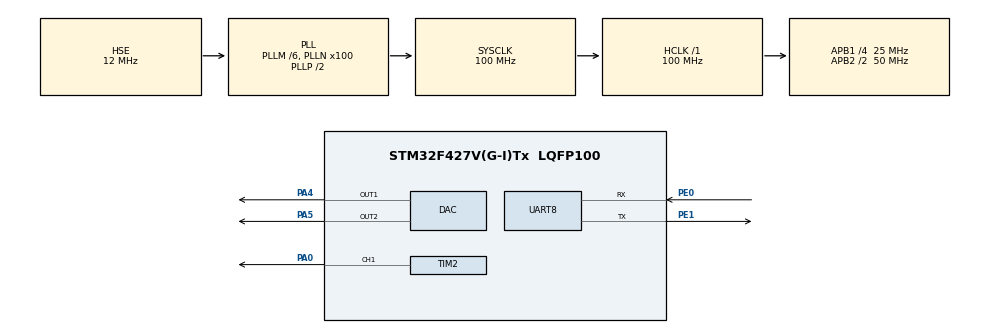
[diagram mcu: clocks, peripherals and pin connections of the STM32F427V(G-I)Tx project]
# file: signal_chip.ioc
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DAC.DAC_Trigger=DAC_TRIGGER_SOFTWARE
DAC.DAC_Trigger2=DAC_TRIGGER_SOFTWARE
Mcu.Family=STM32F4
Mcu.Name=STM32F427V(G-I)Tx
Mcu.Package=LQFP100
NVIC.PriorityGroup=NVIC_PRIORITYGROUP_2
NVIC.UART8_IRQn=true\:2\:2\:true\:false\:true\:true\:true
PA0/WKUP.Signal=S_TIM2_CH1_ETR
PA13.Mode=Serial_Wire
PA13.Signal=SYS_JTMS-SWDIO
PA14.Mode=Serial_Wire
PA14.Signal=SYS_JTCK-SWCLK
PA4.Signal=COMP_DAC1_group
PA5.Signal=COMP_DAC2_group
PE0.Mode=Asynchronous
PE0.Signal=UART8_RX
PE1.Mode=Asynchronous
PE1.Signal=UART8_TX
PH0/OSC_IN.Mode=HSE-External-Oscillator
PH0/OSC_IN.Signal=RCC_OSC_IN
PH1/OSC_OUT.Mode=HSE-External-Oscillator
PH1/OSC_OUT.Signal=RCC_OSC_OUT
ProjectManager.HeapSize=0x200
ProjectManager.StackSize=0x400
ProjectManager.TargetToolchain=MDK-ARM V5
RCC.48MHZClocksFreq_Value=50000000
RCC.AHBFreq_Value=100000000
RCC.APB1CLKDivider=RCC_HCLK_DIV4
RCC.APB1Freq_Value=25000000
RCC.APB1TimFreq_Value=50000000
RCC.APB2CLKDivider=RCC_HCLK_DIV2
RCC.APB2Freq_Value=50000000
RCC.APB2TimFreq_Value=100000000
RCC.CortexFreq_Value=100000000
RCC.HCLKFreq_Value=100000000
RCC.HSE_VALUE=12000000
RCC.HSI_VALUE=16000000
RCC.LSE_VALUE=32768
RCC.PLLM=6
RCC.PLLN=100
RCC.PLLSourceVirtual=RCC_PLLSOURCE_HSE
RCC.SYSCLKFreq_VALUE=100000000
RCC.SYSCLKSource=RCC_SYSCLKSOURCE_PLLCLK
RCC.VCOOutputFreq_Value=200000000
SH.COMP_DAC1_group.0=DAC_OUT1,DAC_OUT1
SH.COMP_DAC2_group.0=DAC_OUT2,DAC_OUT2
SH.S_TIM2_CH1_ETR.0=TIM2_CH1,Output Compare1 CH1
TIM2.Channel-Output\ Compare1\ CH1=TIM_CHANNEL_1
TIM2.Period=1000
TIM2.Prescaler=50
UART8.VirtualMode=Asynchronous
VP_TIM2_VS_ClockSourceINT.Mode=Internal
board=custom

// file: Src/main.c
/* USER CODE BEGIN Header */
/**
  ******************************************************************************
  * @file           : main.c
  * @brief          : Main program body
  ******************************************************************************
  * @attention
  *
  * <h2><center>&copy; Copyright (c) 2019 STMicroelectronics.
  * All rights reserved.</center></h2>
  *
  * This software component is licensed by ST under BSD 3-Clause license,
  * the "License"; You may not use this file except in compliance with the
  * License. You may obtain a copy of the License at:
  *                        opensource.org/licenses/BSD-3-Clause
  *
  ******************************************************************************
  */
/* USER CODE END Header */

#include "main.h"

/* USER CODE BEGIN Includes */
#include "set_coordinates.h"

/* USER CODE END Includes */

DAC_HandleTypeDef hdac;

TIM_HandleTypeDef htim2;

UART_HandleTypeDef huart8;

void SystemClock_Config(void);
static void MX_GPIO_Init(void);
static void MX_DAC_Init(void);
static void MX_TIM2_Init(void);
static void MX_UART8_Init(void);

/* USER CODE BEGIN 0 */
void HAL_UART_RxCpltCallback(UART_HandleTypeDef *huart)
{
  /* Prevent unused argument(s) compilation warning */
  //UNUSED(huart);
  /* NOTE: This function should not be modified, when the callback is needed,
           the HAL_UART_RxCpltCallback could be implemented in the user file
   */
}
/* USER CODE END 0 */

int main(void)
{

  /* MCU Configuration--------------------------------------------------------*/

  /* Reset of all peripherals, Initializes the Flash interface and the Systick. */
  HAL_Init();

  /* Configure the system clock */
  SystemClock_Config();

  /* Initialize all configured peripherals */
  MX_GPIO_Init();
  MX_DAC_Init();
  MX_TIM2_Init();
  MX_UART8_Init();

  /* Infinite loop */
  while (1)
  {

    /* USER CODE BEGIN 3 */
		set_coordinate();
  }
  /* USER CODE END 3 */
}

void SystemClock_Config(void)
{
  RCC_OscInitTypeDef RCC_OscInitStruct = {0};
  RCC_ClkInitTypeDef RCC_ClkInitStruct = {0};

  /** Configure the main internal regulator output voltage
  */
  __HAL_RCC_PWR_CLK_ENABLE();
  __HAL_PWR_VOLTAGESCALING_CONFIG(PWR_REGULATOR_VOLTAGE_SCALE3);
  /** Initializes the CPU, AHB and APB busses clocks
  */
  RCC_OscInitStruct.OscillatorType = RCC_OSCILLATORTYPE_HSE;
  RCC_OscInitStruct.HSEState = RCC_HSE_ON;
  RCC_OscInitStruct.PLL.PLLState = RCC_PLL_ON;
  RCC_OscInitStruct.PLL.PLLSource = RCC_PLLSOURCE_HSE;
  RCC_OscInitStruct.PLL.PLLM = 6;
  RCC_OscInitStruct.PLL.PLLN = 100;
  RCC_OscInitStruct.PLL.PLLP = RCC_PLLP_DIV2;
  RCC_OscInitStruct.PLL.PLLQ = 4;
  if (HAL_RCC_OscConfig(&RCC_OscInitStruct) != HAL_OK)
  {
    Error_Handler();
  }
  /** Initializes the CPU, AHB and APB busses clocks
  */
  RCC_ClkInitStruct.ClockType = RCC_CLOCKTYPE_HCLK|RCC_CLOCKTYPE_SYSCLK
                              |RCC_CLOCKTYPE_PCLK1|RCC_CLOCKTYPE_PCLK2;
  RCC_ClkInitStruct.SYSCLKSource = RCC_SYSCLKSOURCE_PLLCLK;
  RCC_ClkInitStruct.AHBCLKDivider = RCC_SYSCLK_DIV1;
  RCC_ClkInitStruct.APB1CLKDivider = RCC_HCLK_DIV4;
  RCC_ClkInitStruct.APB2CLKDivider = RCC_HCLK_DIV2;

  if (HAL_RCC_ClockConfig(&RCC_ClkInitStruct, FLASH_LATENCY_3) != HAL_OK)
  {
    Error_Handler();
  }
}

static void MX_DAC_Init(void)
{

  DAC_ChannelConfTypeDef sConfig = {0};

  /** DAC Initialization
  */
  hdac.Instance = DAC;
  if (HAL_DAC_Init(&hdac) != HAL_OK)
  {
    Error_Handler();
  }
  /** DAC channel OUT1 config
  */
  sConfig.DAC_Trigger = DAC_TRIGGER_SOFTWARE;
  sConfig.DAC_OutputBuffer = DAC_OUTPUTBUFFER_ENABLE;
  if (HAL_DAC_ConfigChannel(&hdac, &sConfig, DAC_CHANNEL_1) != HAL_OK)
  {
    Error_Handler();
  }
  /** DAC channel OUT2 config
  */
  if (HAL_DAC_ConfigChannel(&hdac, &sConfig, DAC_CHANNEL_2) != HAL_OK)
  {
    Error_Handler();
  }

}

static void MX_TIM2_Init(void)
{

  TIM_ClockConfigTypeDef sClockSourceConfig = {0};
  TIM_MasterConfigTypeDef sMasterConfig = {0};
  TIM_OC_InitTypeDef sConfigOC = {0};

  htim2.Instance = TIM2;
  htim2.Init.Prescaler = 50;
  htim2.Init.CounterMode = TIM_COUNTERMODE_UP;
  htim2.Init.Period = 1000;
  htim2.Init.ClockDivision = TIM_CLOCKDIVISION_DIV1;
  htim2.Init.AutoReloadPreload = TIM_AUTORELOAD_PRELOAD_DISABLE;
  if (HAL_TIM_Base_Init(&htim2) != HAL_OK)
  {
    Error_Handler();
  }
  sClockSourceConfig.ClockSource = TIM_CLOCKSOURCE_INTERNAL;
  if (HAL_TIM_ConfigClockSource(&htim2, &sClockSourceConfig) != HAL_OK)
  {
    Error_Handler();
  }
  if (HAL_TIM_OC_Init(&htim2) != HAL_OK)
  {
    Error_Handler();
  }
  sMasterConfig.MasterOutputTrigger = TIM_TRGO_RESET;
  sMasterConfig.MasterSlaveMode = TIM_MASTERSLAVEMODE_DISABLE;
  if (HAL_TIMEx_MasterConfigSynchronization(&htim2, &sMasterConfig) != HAL_OK)
  {
    Error_Handler();
  }
  sConfigOC.OCMode = TIM_OCMODE_TIMING;
  sConfigOC.Pulse = 0;
  sConfigOC.OCPolarity = TIM_OCPOLARITY_HIGH;
  sConfigOC.OCFastMode = TIM_OCFAST_DISABLE;
  if (HAL_TIM_OC_ConfigChannel(&htim2, &sConfigOC, TIM_CHANNEL_1) != HAL_OK)
  {
    Error_Handler();
  }
  HAL_TIM_MspPostInit(&htim2);

}

static void MX_UART8_Init(void)
{

  huart8.Instance = UART8;
  huart8.Init.BaudRate = 115200;
  huart8.Init.WordLength = UART_WORDLENGTH_8B;
  huart8.Init.StopBits = UART_STOPBITS_1;
  huart8.Init.Parity = UART_PARITY_NONE;
  huart8.Init.Mode = UART_MODE_TX_RX;
  huart8.Init.HwFlowCtl = UART_HWCONTROL_NONE;
  huart8.Init.OverSampling = UART_OVERSAMPLING_16;
  if (HAL_UART_Init(&huart8) != HAL_OK)
  {
    Error_Handler();
  }

}

static void MX_GPIO_Init(void)
{

  /* GPIO Ports Clock Enable */
  __HAL_RCC_GPIOH_CLK_ENABLE();
  __HAL_RCC_GPIOA_CLK_ENABLE();
  __HAL_RCC_GPIOE_CLK_ENABLE();

}

void Error_Handler(void)
{
}

/************************ (C) COPYRIGHT STMicroelectronics *****END OF FILE****/
